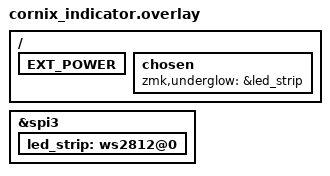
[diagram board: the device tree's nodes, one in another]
// #include <zephyr/dt-bindings/led/led.h>
&spi3 {
    status = "okay";

   led_strip: ws2812@0 {
        status = "okay";
    };
};

/ {

    EXT_POWER {
        status = "okay";
    };

    chosen {
        zmk,underglow = &led_strip;
    };
};

